# UPD70F3508 register map
Vendor: Renesas; Series: V850E2/Px4; File version: 1.0
CPU: other r0p0, little endian, no MPU, FPU, 4 interrupt priority bits
Registers are 8-bit, read-write, reset 0x0 unless marked. A register's access mark holds for its fields unless they carry their own. Offsets are from the block's base; [hi:lo] are bit positions; {n}, {i} and the like mark numbered series.

## ADCA0_CTRL — A/D Converter A0 - Control/Config register block (ADCAn_base0=0xFF81D000, offsets 0x100-0x123)
Base 0xFF81D100
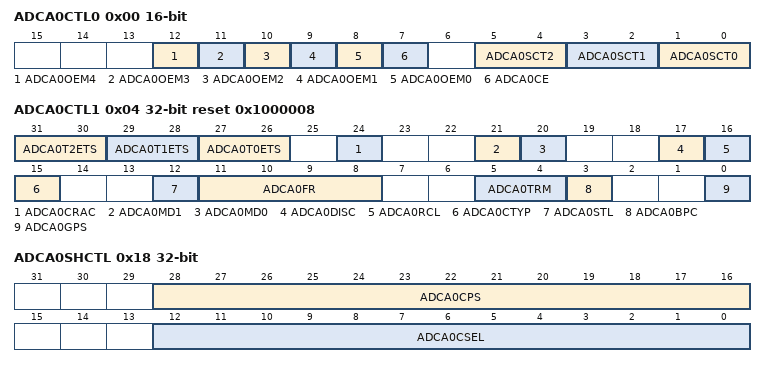
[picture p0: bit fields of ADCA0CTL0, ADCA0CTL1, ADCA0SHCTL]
0x00 ADCA0CTL0 16-bit — A/D Converter Mode Control Register 0
  [12] ADCA0OEM4 — Error interrupt mask for LCR overwrite (0=generate, 1=suppress)
  [11] ADCA0OEM3 — Error interrupt mask for DB2CR overwrite
  [10] ADCA0OEM2 — Error interrupt mask for DB1CR overwrite
  [9] ADCA0OEM1 — Error interrupt mask for DB0CR overwrite
  [8] ADCA0OEM0 — Error interrupt mask for CmCR overwrite
  [7] ADCA0CE — A/D converter enable (0=disable, 1=enable)
  [5:4] ADCA0SCT2 — CG2 scan list repetitions in one-shot mode (00=1,01=2,10=3,11=4)
  [3:2] ADCA0SCT1 — CG1 scan list repetitions in one-shot mode
  [1:0] ADCA0SCT0 — CG0 scan list repetitions in one-shot mode
0x04 ADCA0CTL1 32-bit reset 0x1000008 — A/D Converter Mode Control Register 1
  [31:30] ADCA0T2ETS — Valid edge of HW trigger ADCAnTTRG2 (00=none,01=rise,10=fall,11=both)
  [29:28] ADCA0T1ETS — Valid edge of HW trigger ADCAnTTRG1
  [27:26] ADCA0T0ETS — Valid edge of HW trigger ADCAnTTRG0
  [24] ADCA0CRAC — Conversion result alignment (0=right-aligned, 1=left-aligned)
  [21] ADCA0MD1 — CG0 start trigger mode (0=SW only, 1=HW+SW)
  [20] ADCA0MD0 — CG0 conversion mode (0=one-shot, 1=continuous)
  [17] ADCA0DISC — Discharge function enable (0=disable, 1=enable)
  [16] ADCA0RCL — Result clear-on-read (0=retain until overwrite, 1=clear after read)
  [15] ADCA0CTYP — Resolution select (0=12-bit, 1=10-bit)
  [12] ADCA0STL — ADCAnCNVi signal polarity (0=high=active, 1=low=active)
  [11:8] ADCA0FR — ADCAnTCLK clock divider (0000=PCLK/2 ... 1110=PCLK/16)
  [5:4] ADCA0TRM — Higher-priority interrupt behavior (bit5=CG1, bit4=CG0)
  [3] ADCA0BPC — Buffer amplifier enable (0=disable, 1=enable)
  [0] ADCA0GPS — A/D converter power (0=off, 1=on)
{0x8+4i} ADCA0TSEL{i} 16-bit (i=0..2) — A/D Converter Trigger Select Control Register {i} (CG{i})
  [15:0] ADCA0T{i}SEL — HW trigger source select bitmask for CG{i} (bit n=TTINn0n)
0x14 ADCA0CNT — A/D Converter Stabilization Counter
  [7:0] ADCA0CNT — Stabilization time = CNT[7:0] x PCLK cycles
0x18 ADCA0SHCTL 32-bit — A/D Converter Channel Sample and Hold Control Register
  [28:16] ADCA0CPS — Channel S/H power supply control bits [12:0] (bit x-1 = CHx)
  [12:0] ADCA0CSEL — Channel S/H function enable bits [12:0] (bit x-1 = CHx)
0x1C ADCA0DGCTL1 32-bit — A/D Converter Self-Diagnosis Function Control Register 1
  [23:0] ADCA0CDG — Diagnostic voltage select per channel (0=analog pin, 1=reference voltage)
0x20 ADCA0PDCTL0 32-bit — A/D Converter Internal Pull-Down Resistance Control Register 0
  [23:0] ADCA0PDNA — Internal pull-down resistor per channel (bit n-1 = CHn)

## PIC0_CTRL — Peripheral Interconnection Controller 0 — isolated control registers (PIC0EN enable + PIC0SST simultaneous start trigger)
Base 0xFF81DB00
0x00 PIC0EN — Control register EN — enables or disables all PIC functions (PIC0EN0 bit)
  [0] PIC0EN0 — Enable PIC functions (0=disable, 1=enable)

## TPBA0 — Timer Pulse Buffer Array 0 — 16-bit PWM timer with duty setting buffer (instance 0)
Base 0xFF832000
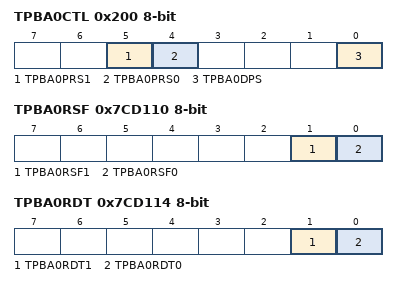
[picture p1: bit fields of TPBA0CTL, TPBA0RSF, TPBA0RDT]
0x200 TPBA0CTL — TPBA0 Control Register — selects count clock prescaler and duty pattern mode
  [5] TPBA0PRS1 — Count clock prescaler select bit 1 (with PRS0: 00=PCLK, 01=PCLK/2, 10=PCLK/4, 11=PCLK/8)
  [4] TPBA0PRS0 — Count clock prescaler select bit 0
  [0] TPBA0DPS — Duty setting pattern mode: 0=16-bit 64-patterns, 1=8-bit 128-patterns
0x7CD000 TPBA0BUF00 16-bit — TPBA0 Duty Setting Register 00 (representative; BUF01..BUF63 at base1+0x004*m, m=0..63). Sets duty value for pattern 1 (16-bit mode) or patterns 1-2 (8-bit mode).
  [15:0] TPBA0BUF00 — Duty value bits [15:0]
0x7CD100 TPBA0CMP0 16-bit — TPBA0 Period Setting Register — 16-bit compare register; PWM period = (CMP0+1) × count clock
  [15:0] TPBA0CMP0 — Period compare value [15:0]
0x7CD104 TPBA0CMP1 — TPBA0 Pattern Number Setting Register — sets number of PWM output patterns [6:0]
  [6:0] TPBA0CMP1 — Number of patterns [6:0] (0-63 in 16-bit mode, 0-127 in 8-bit mode)
0x7CD108 TPBA0CNT0 16-bit ro reset 0xFFFF — TPBA0 Timer Counter Register — 16-bit counter current value (read-only)
  [15:0] TPBA0CNT0 — 16-bit counter value [15:0]
0x7CD10C TPBA0CNT1 ro — TPBA0 Address Counter Register — 7-bit counter indicating address pointer to duty setting register
  [6:0] TPBA0CNT1 — 7-bit address counter value [6:0]
0x7CD110 TPBA0RSF ro — TPBA0 Reload Status Register — indicates pending reload requests
  [1] TPBA0RSF1 — Reload request flag for CMP1: 0=none/complete, 1=reload request pending
  [0] TPBA0RSF0 — Reload request flag for CMP0 and TOL: 0=none/complete, 1=reload request pending
0x7CD114 TPBA0RDT wo — TPBA0 Reload Data Trigger Register — enables reload of compare/output-level registers (always read as 0)
  [1] TPBA0RDT1 — Reload enable for CMP1: writing 1 enables reload (sets RSF1); 0 is ignored
  [0] TPBA0RDT0 — Reload enable for CMP0 and TOL: writing 1 enables reload (sets RSF0); 0 is ignored
0x7CD118 TPBA0RDM — TPBA0 Reload Data Mode Register — controls reload timing of CMP0 and TOL
  [0] TPBA0RDM0 — Reload timing: 0=synchronous with INTTPBAnIPAT, 1=synchronous with INTTPBAnIPRD
0x7CD11C TPBA0TO — TPBA0 Timer Output Register — reads/sets TPBnO pin output level
  [0] TPBA0TO0 — Output level: 0=low, 1=high (write ignored when timer output enabled)
0x7CD120 TPBA0TOE — TPBA0 Timer Output Enable Register — enables/disables PWM output from TPBnO pin
  [0] TPBA0TOE0 — Timer output enable: 0=output disabled (software control via TO), 1=PWM output enabled
0x7CD124 TPBA0TOL — TPBA0 Timer Output Level Register — specifies active level of PWM output (reload register)
  [0] TPBA0TOL0 — Active output level: 0=high active, 1=low active
0x7CD128 TPBA0TE ro — TPBA0 Enable Status Register — indicates whether timer counter is running
  [0] TPBA0TE0 — Timer enable status: 0=stopped, 1=operating
0x7CD12C TPBA0TS wo — TPBA0 Start Trigger Register — writing 1 starts the timer counter (always read as 0)
  [0] TPBA0TS0 — Start trigger: 0=ignored, 1=starts counting (TE0 set to 1)
0x7CD130 TPBA0TT wo — TPBA0 Stop Trigger Register — writing 1 stops the timer counter (always read as 0)
  [0] TPBA0TT0 — Stop trigger: 0=ignored, 1=stops counting (TE0 cleared to 0)
